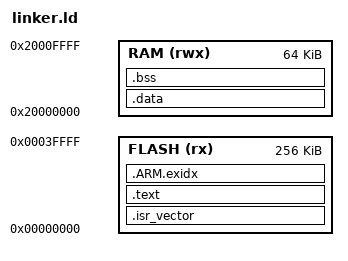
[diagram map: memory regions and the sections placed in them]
/* Minimal Cortex-M3 memory map for QEMU lm3s6965evb. */

ENTRY(Reset_Handler)

MEMORY
{
  FLASH (rx)  : ORIGIN = 0x00000000, LENGTH = 256K
  RAM   (rwx) : ORIGIN = 0x20000000, LENGTH = 64K
}

_estack = ORIGIN(RAM) + LENGTH(RAM);

SECTIONS
{
  .isr_vector :
  {
    KEEP(*(.isr_vector))
  } > FLASH

  .text :
  {
    *(.text*)
    *(.rodata*)
    *(.glue_7)
    *(.glue_7t)
    *(.eh_frame*)
    KEEP(*(.init))
    KEEP(*(.fini))
    . = ALIGN(4);
  } > FLASH

  /* Exception unwinding info (not strictly needed, but harmless). */
  .ARM.exidx :
  {
    __exidx_start = .;
    *(.ARM.exidx*)
    __exidx_end = .;
  } > FLASH

  .data : AT(LOADADDR(.text) + SIZEOF(.text) + SIZEOF(.ARM.exidx))
  {
    . = ALIGN(4);
    _sdata = .;
    *(.data*)
    . = ALIGN(4);
    _edata = .;
  } > RAM

  _sidata = LOADADDR(.data);

  .bss :
  {
    . = ALIGN(4);
    _sbss = .;
    *(.bss*)
    *(COMMON)
    . = ALIGN(4);
    _ebss = .;
  } > RAM

  /* newlib/rdimon expect an `end` symbol for heap start (_sbrk). */
  end = .;
  _end = .;
  __end__ = .;

  /DISCARD/ :
  {
    *(.note*)
    *(.comment*)
  }
}

